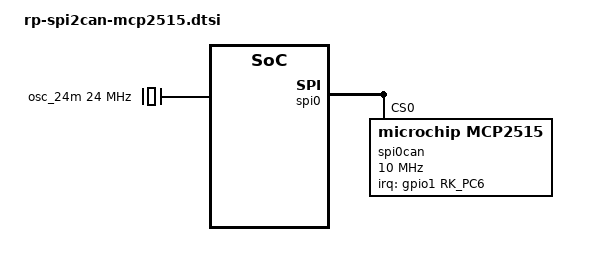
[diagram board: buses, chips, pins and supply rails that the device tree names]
/{
    /** 24M osc clock to mcp2515 */
    osc_24m: osc24m {
        compatible = "fixed-clock";
        #clock-cells = <0>;
        clock-frequency = <24000000>;
    };

};

&spi0 {
    status = "okay";

    /* rewrite pinctrl for cs1 used to be camera clk */
    pinctrl-0 = <&spi0m0_cs0 &spi0m0_pins>;

    spi0can: mcp2515@0 {
        status = "okay";
        compatible = "microchip,mcp2515";
        reg = <0>;
        clocks = <&osc_24m>;
        interrupt-parent = <&gpio1>;
        interrupts = <RK_PC6 IRQ_TYPE_LEVEL_LOW>;
        // vdd-supply = <&reg5v0>;
        // xceiver-supply = <&reg5v0>;
        spi-max-frequency = <10000000>;
    };
};
